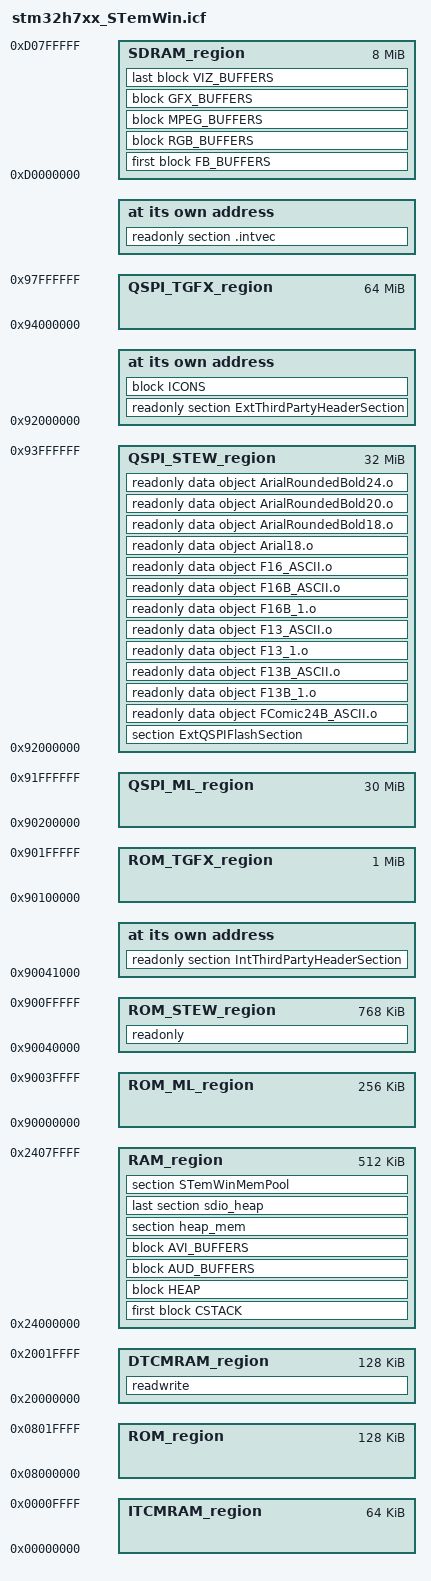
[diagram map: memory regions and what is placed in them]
/*###ICF### Section handled by ICF editor, don't touch! ****/
/*-Editor annotation file-*/
/* IcfEditorFile="$TOOLKIT_DIR$\config\ide\IcfEditor\cortex_v1_0.xml" */
/*-Specials-*/
define symbol __ICFEDIT_intvec_start__ = __C_START_ADDR; /* 0x90040000 */
/*-Memory Regions-*/
define symbol __ICFEDIT_region_ROM_start__        = 0x08000000;
define symbol __ICFEDIT_region_ROM_end__          = 0x0801FFFF; /*  128 Kbytes for the Menu Launcher */

define symbol __ICFEDIT_region_ROM_ML_start__     = 0x90000000;
define symbol __ICFEDIT_region_ROM_ML_end__       = 0x9003FFFF; /*  256 bytes for the Menu Launcher */
define symbol __ICFEDIT_region_ROM_STEW_start__   = 0x90040000;
define symbol __ICFEDIT_region_ROM_STEW_end__     = 0x900FFFFF; /*  768 Kbytes for STemWin demo */
define symbol __ICFEDIT_region_ROM_TGFX_start__   = 0x90100000;
define symbol __ICFEDIT_region_ROM_TGFX_end__     = 0x901FFFFF; /* 1024 Kbytes for TouchGFX demo */

/*-Internal RAM Memory Regions-*/
define symbol __ICFEDIT_region_ITCMRAM_start__    = 0x00000000;
define symbol __ICFEDIT_region_ITCMRAM_end__      = 0x0000FFFF; /*  64 Kbytes */
define symbol __ICFEDIT_region_DTCMRAM_start__    = 0x20000000;
define symbol __ICFEDIT_region_DTCMRAM_end__      = 0x2001FFFF; /* 128 Kbytes */
define symbol __ICFEDIT_region_RAM_start__        = 0x24000000;
define symbol __ICFEDIT_region_RAM_end__          = 0x2407FFFF; /* 512 Kbytes */

/*-External RAM Memory Regions-*/
define symbol __ICFEDIT_region_SDRAM_start__      = 0xD0000000; /*   8 Mbytes */
define symbol __ICFEDIT_region_SDRAM_end__        = 0xD07FFFFF;

/*-Quad-SPI Memory Regions-*/
define symbol __ICFEDIT_region_QSPI_ML_start__    = 0x90200000;
define symbol __ICFEDIT_region_QSPI_ML_end__      = 0x91FFFFFF; /* 30 Mbytes for the MenuLauncher */
define symbol __ICFEDIT_region_QSPI_STEW_start__  = 0x92000000;
define symbol __ICFEDIT_region_QSPI_STEW_end__    = 0x93FFFFFF; /* 32 Mbytes for STemWin demo */
define symbol __ICFEDIT_region_QSPI_TGFX_start__  = 0x94000000;
define symbol __ICFEDIT_region_QSPI_TGFX_end__    = 0x97FFFFFF; /* 64 Mbytes for TouchGFX demo */

/*-Sizes-*/
define symbol __ICFEDIT_size_cstack__ = 0x800;  /* 2 Kb */
define symbol __ICFEDIT_size_heap__   = 0x800;  /* 2 Kb */
/**** End of ICF editor section. ###ICF###*/

define memory mem with size = 4G;
define region ROM_region        = mem:[from __ICFEDIT_region_ROM_start__        to __ICFEDIT_region_ROM_end__];
define region ROM_ML_region     = mem:[from __ICFEDIT_region_ROM_ML_start__     to __ICFEDIT_region_ROM_ML_end__];
define region ROM_STEW_region   = mem:[from __ICFEDIT_region_ROM_STEW_start__   to __ICFEDIT_region_ROM_STEW_end__];
define region ROM_TGFX_region   = mem:[from __ICFEDIT_region_ROM_TGFX_start__   to __ICFEDIT_region_ROM_TGFX_end__];

define region ITCMRAM_region    = mem:[from __ICFEDIT_region_ITCMRAM_start__    to __ICFEDIT_region_ITCMRAM_end__];
define region DTCMRAM_region    = mem:[from __ICFEDIT_region_DTCMRAM_start__    to __ICFEDIT_region_DTCMRAM_end__];
define region RAM_region        = mem:[from __ICFEDIT_region_RAM_start__        to __ICFEDIT_region_RAM_end__];
define region SDRAM_region      = mem:[from __ICFEDIT_region_SDRAM_start__      to __ICFEDIT_region_SDRAM_end__];

define region QSPI_ML_region    = mem:[from __ICFEDIT_region_QSPI_ML_start__    to __ICFEDIT_region_QSPI_ML_end__];
define region QSPI_STEW_region  = mem:[from __ICFEDIT_region_QSPI_STEW_start__  to __ICFEDIT_region_QSPI_STEW_end__];
define region QSPI_TGFX_region  = mem:[from __ICFEDIT_region_QSPI_TGFX_start__  to __ICFEDIT_region_QSPI_TGFX_end__];

define block CSTACK     with alignment =  8, size = __ICFEDIT_size_cstack__    { };
define block HEAP       with alignment =  8, size = __ICFEDIT_size_heap__      { };
define block ICONS      with alignment = 32 { section demo_icon_section, section demo_logo_section };
define block RGB_BUFFERS  with alignment = 32   { first section rgb_video_buffers };        /* 2 * (800 * 480 * 2 bytes) : 1500 Kb */
define block MPEG_BUFFERS with alignment = 32   { first section jpeg_decoder_buffers };
define block GFX_BUFFERS  with alignment = 256  { first section gfx_buffers }; /* 12 Mbytes */
define block AUD_BUFFERS  with alignment = 32   { first section audio_buffers };
define block VIZ_BUFFERS  with alignment = 32   { first section viz_front_buffer, section viz_back_buffer, section viz_deform_x_buffer, section viz_deform_y_buffer, section viz_bitmap_buffer };
define block AVI_BUFFERS  with alignment = 32   { first section avi_video_buffers };
define block FB_BUFFERS with alignment = 32, fixed order                      { section framebuffer, section dma2d_palette };
/*-Third Party Demonstration Headers-*/
define symbol __thp_int_header_start__ = __ICFEDIT_region_ROM_STEW_start__ + 0x1000;
define symbol __thp_ext_header_start__ = __ICFEDIT_region_QSPI_STEW_start__;

initialize by copy { readwrite };
initialize manually { readonly data section DemoLoaderSection };
do not initialize  { section .noinit };
do not initialize  { section framebuffer, section dma2d_palette };
do not initialize  { section jpeg_decoder_buffers, section rgb_video_buffers, section gfx_buffers };
do not initialize  { section viz_front_buffer, section viz_back_buffer, section viz_deform_x_buffer, section viz_deform_y_buffer, section viz_bitmap_buffer };

place at address mem:__ICFEDIT_intvec_start__ { readonly section .intvec };

/*-Third Party headers Memory Placement-*/
place at address mem:__thp_int_header_start__   { readonly section IntThirdPartyHeaderSection };
place at address mem:__thp_ext_header_start__   { readonly section ExtThirdPartyHeaderSection, block ICONS };

place in ITCMRAM_region     { };
place in DTCMRAM_region     { readwrite };
place in RAM_region         { first block CSTACK, block HEAP
                            , block AUD_BUFFERS
                            , block AVI_BUFFERS
                            , section heap_mem, last section sdio_heap, section STemWinMemPool };

place in SDRAM_region       { first block FB_BUFFERS
                            , block RGB_BUFFERS
                            , block MPEG_BUFFERS
                            , block GFX_BUFFERS
                            , last block VIZ_BUFFERS };
							
place in ROM_STEW_region    { readonly };

place in QSPI_STEW_region   { section ExtQSPIFlashSection
                            , readonly data object FComic24B_ASCII.o
                            , readonly data object F13B_1.o
                            , readonly data object F13B_ASCII.o
                            , readonly data object F13_1.o
                            , readonly data object F13_ASCII.o
                            , readonly data object F16B_1.o
                            , readonly data object F16B_ASCII.o
                            , readonly data object F16_ASCII.o
                            , readonly data object Arial18.o
                            , readonly data object ArialRoundedBold18.o
                            , readonly data object ArialRoundedBold20.o
                            , readonly data object ArialRoundedBold24.o };
